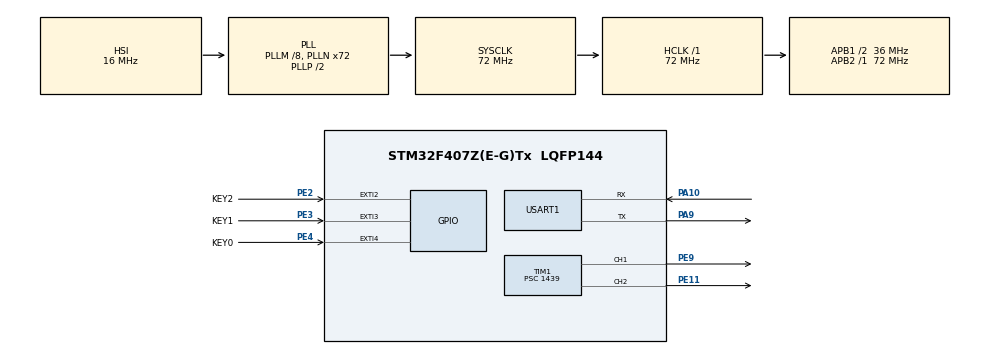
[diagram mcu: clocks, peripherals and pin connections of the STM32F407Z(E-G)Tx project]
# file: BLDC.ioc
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Mcu.Family=STM32F4
Mcu.Name=STM32F407Z(E-G)Tx
Mcu.Package=LQFP144
NVIC.EXTI2_IRQn=true\:2\:0\:true\:false\:true\:true\:true\:true
NVIC.EXTI3_IRQn=true\:2\:0\:true\:false\:true\:true\:true\:true
NVIC.EXTI4_IRQn=true\:2\:0\:true\:false\:true\:true\:true\:true
NVIC.PriorityGroup=NVIC_PRIORITYGROUP_4
NVIC.TIM1_BRK_TIM9_IRQn=true\:0\:0\:false\:false\:true\:true\:true\:true
NVIC.TIM1_CC_IRQn=true\:0\:0\:false\:false\:true\:true\:true\:true
NVIC.TIM1_TRG_COM_TIM11_IRQn=true\:0\:0\:false\:false\:true\:true\:true\:true
NVIC.TIM1_UP_TIM10_IRQn=true\:0\:0\:false\:false\:true\:true\:true\:true
NVIC.USART1_IRQn=true\:0\:0\:false\:false\:true\:true\:true\:true
PA10.Mode=Asynchronous
PA10.Signal=USART1_RX
PA9.Mode=Asynchronous
PA9.Signal=USART1_TX
PC14-OSC32_IN.Mode=LSE-External-Clock-Source
PC14-OSC32_IN.Signal=RCC_OSC32_IN
PC15-OSC32_OUT.Mode=LSE-External-Clock-Source
PC15-OSC32_OUT.Signal=RCC_OSC32_OUT
PE11.Signal=S_TIM1_CH2
PE2.GPIO_Label=KEY2
PE2.GPIO_ModeDefaultEXTI=GPIO_MODE_IT_FALLING
PE2.GPIO_PuPd=GPIO_PULLUP
PE2.Signal=GPXTI2
PE3.GPIO_Label=KEY1
PE3.GPIO_ModeDefaultEXTI=GPIO_MODE_IT_FALLING
PE3.GPIO_PuPd=GPIO_PULLUP
PE3.Signal=GPXTI3
PE4.GPIO_Label=KEY0
PE4.GPIO_ModeDefaultEXTI=GPIO_MODE_IT_FALLING
PE4.GPIO_PuPd=GPIO_PULLUP
PE4.Signal=GPXTI4
PE9.Signal=S_TIM1_CH1
PH0-OSC_IN.Mode=HSE-External-Clock-Source
PH0-OSC_IN.Signal=RCC_OSC_IN
PH1-OSC_OUT.Mode=HSE-External-Clock-Source
PH1-OSC_OUT.Signal=RCC_OSC_OUT
ProjectManager.HeapSize=0x200
ProjectManager.StackSize=0x400
ProjectManager.TargetToolchain=CMake
RCC.48MHZClocksFreq_Value=36000000
RCC.AHBFreq_Value=72000000
RCC.APB1CLKDivider=RCC_HCLK_DIV2
RCC.APB1Freq_Value=36000000
RCC.APB1TimFreq_Value=72000000
RCC.APB2Freq_Value=72000000
RCC.APB2TimFreq_Value=72000000
RCC.CortexFreq_Value=72000000
RCC.HCLKFreq_Value=72000000
RCC.HSE_VALUE=8000000
RCC.HSI_VALUE=16000000
RCC.LSE_VALUE=32768
RCC.PLLM=8
RCC.PLLN=72
RCC.SYSCLKFreq_VALUE=72000000
RCC.SYSCLKSource=RCC_SYSCLKSOURCE_PLLCLK
RCC.VCOOutputFreq_Value=144000000
SH.S_TIM1_CH1.0=TIM1_CH1,PWM Generation1 CH1
SH.S_TIM1_CH2.0=TIM1_CH2,PWM Generation2 CH2
TIM1.Channel-PWM\ Generation1\ CH1=TIM_CHANNEL_1
TIM1.Channel-PWM\ Generation2\ CH2=TIM_CHANNEL_2
TIM1.Period=999
TIM1.Prescaler=1439
USART1.VirtualMode=VM_ASYNC
VP_TIM1_VS_ClockSourceINT.Mode=Internal
board=custom

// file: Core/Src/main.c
/* USER CODE BEGIN Header */
/**
 ******************************************************************************
 * @file           : main.c
 * @brief          : Main program body
 ******************************************************************************
 * @attention
 *
 * Copyright (c) 2024 STMicroelectronics.
 * All rights reserved.
 *
 * This software is licensed under terms that can be found in the LICENSE file
 * in the root directory of this software component.
 * If no LICENSE file comes with this software, it is provided AS-IS.
 *
 ******************************************************************************
 */
/* USER CODE END Header */
#include "main.h"
#include "tim.h"
#include "usart.h"
#include "gpio.h"

/* USER CODE BEGIN Includes */
#include <stdio.h>
/* USER CODE END Includes */

void SystemClock_Config(void);
/* USER CODE BEGIN PFP */
int __io_putchar(int ch);
/* USER CODE END PFP */

int main(void)
{

  /* MCU Configuration--------------------------------------------------------*/

  /* Reset of all peripherals, Initializes the Flash interface and the Systick. */
  HAL_Init();

  /* Configure the system clock */
  SystemClock_Config();

  /* Initialize all configured peripherals */
  MX_GPIO_Init();
  MX_TIM1_Init();
  MX_USART1_UART_Init();
  /* USER CODE BEGIN 2 */

  printf("Program Start.\n");
  HAL_TIM_PWM_Start(&htim1, TIM_CHANNEL_1);
  HAL_TIM_PWM_Start(&htim1, TIM_CHANNEL_2);

  /* USER CODE END 2 */

  /* Infinite loop */
  while (1) {

  }
}

void SystemClock_Config(void)
{
  RCC_OscInitTypeDef RCC_OscInitStruct = {0};
  RCC_ClkInitTypeDef RCC_ClkInitStruct = {0};

  /** Configure the main internal regulator output voltage
  */
  __HAL_RCC_PWR_CLK_ENABLE();
  __HAL_PWR_VOLTAGESCALING_CONFIG(PWR_REGULATOR_VOLTAGE_SCALE1);

  /** Initializes the RCC Oscillators according to the specified parameters
  * in the RCC_OscInitTypeDef structure.
  */
  RCC_OscInitStruct.OscillatorType = RCC_OSCILLATORTYPE_HSI;
  RCC_OscInitStruct.HSIState = RCC_HSI_ON;
  RCC_OscInitStruct.HSICalibrationValue = RCC_HSICALIBRATION_DEFAULT;
  RCC_OscInitStruct.PLL.PLLState = RCC_PLL_ON;
  RCC_OscInitStruct.PLL.PLLSource = RCC_PLLSOURCE_HSI;
  RCC_OscInitStruct.PLL.PLLM = 8;
  RCC_OscInitStruct.PLL.PLLN = 72;
  RCC_OscInitStruct.PLL.PLLP = RCC_PLLP_DIV2;
  RCC_OscInitStruct.PLL.PLLQ = 4;
  if (HAL_RCC_OscConfig(&RCC_OscInitStruct) != HAL_OK)
  {
    Error_Handler();
  }

  /** Initializes the CPU, AHB and APB buses clocks
  */
  RCC_ClkInitStruct.ClockType = RCC_CLOCKTYPE_HCLK|RCC_CLOCKTYPE_SYSCLK
                              |RCC_CLOCKTYPE_PCLK1|RCC_CLOCKTYPE_PCLK2;
  RCC_ClkInitStruct.SYSCLKSource = RCC_SYSCLKSOURCE_PLLCLK;
  RCC_ClkInitStruct.AHBCLKDivider = RCC_SYSCLK_DIV1;
  RCC_ClkInitStruct.APB1CLKDivider = RCC_HCLK_DIV2;
  RCC_ClkInitStruct.APB2CLKDivider = RCC_HCLK_DIV1;

  if (HAL_RCC_ClockConfig(&RCC_ClkInitStruct, FLASH_LATENCY_2) != HAL_OK)
  {
    Error_Handler();
  }
}

/* USER CODE BEGIN 4 */
int __io_putchar(int ch) {
  HAL_UART_Transmit(&huart1, (uint8_t *)&ch, 1, 0xFFFF);
  return ch;
}
/* USER CODE END 4 */

void Error_Handler(void)
{
  __disable_irq();
  while (1) {
  }
}

#ifdef  USE_FULL_ASSERT
/**
  * @brief  Reports the name of the source file and the source line number
  *         where the assert_param error has occurred.
  * @param  file: pointer to the source file name
  * @param  line: assert_param error line source number
  * @retval None
  */
void assert_failed(uint8_t *file, uint32_t line)
{
  /* USER CODE BEGIN 6 */
  /* User can add his own implementation to report the file name and line
     number, ex: printf("Wrong parameters value: file %s on line %d\r\n", file,
     line) */
  /* USER CODE END 6 */
}
#endif /* USE_FULL_ASSERT */
